# LargeDummyDevice register map
File version: 1.0
Registers are 32-bit, read-write, no defined reset value unless marked. A register's access mark holds for its fields unless they carry their own. Offsets are from the block's base; [hi:lo] are bit positions.

## PERIPHERAL_18
Base 0x40011000
0x04 REG_1 — Register 1
  [32:31] FIELD_7, [29:27] FIELD_13, [23] FIELD_1, [24:22] FIELD_10, [23:19] FIELD_9, [20:18] FIELD_6, [18:16] FIELD_4, [19:15] FIELD_5, [18:15] FIELD_12, [18:14] FIELD_2, [14:12] FIELD_11, [10:6] FIELD_8, [8:5] FIELD_3
0x08 REG_2 — Register 2
  [29] FIELD_7, [28:24] FIELD_13, [23:22] FIELD_3, [24:21] FIELD_8, [24:21] FIELD_11, [21:19] FIELD_9, [20:17] FIELD_1, [16:12] FIELD_12, [13:11] FIELD_10, [12:10] FIELD_2, [8:6] FIELD_6, [5] FIELD_4, [6:5] FIELD_5, [4:1] FIELD_14
0x0C REG_3 — Register 3
  [34:31] FIELD_13, [30:29] FIELD_20, [27] FIELD_19, [27:26] FIELD_18, [29:25] FIELD_5, [27:25] FIELD_14, [24] FIELD_12, [21] FIELD_16, [22:19] FIELD_1, [23:19] FIELD_9, [21:17] FIELD_2, [18:14] FIELD_8, [14] FIELD_17, [17:14] FIELD_24, [14:13] FIELD_22, [13:12] FIELD_21, [15:11] FIELD_11, [12:9] FIELD_3, [11:8] FIELD_6, [9:5] FIELD_4, [6:4] FIELD_10, [4] FIELD_23, [5:3] FIELD_7, [5:1] FIELD_15
0x10 REG_4 — Register 4
  [34:31] FIELD_26, [33:30] FIELD_16, [34:30] FIELD_31, [31:27] FIELD_4, [26] FIELD_5, [30:26] FIELD_29, [29:25] FIELD_6, [27:24] FIELD_11, [26:24] FIELD_24, [24] FIELD_30, [26:23] FIELD_10, [25:23] FIELD_18, [23] FIELD_28, [25:21] FIELD_8, [23:21] FIELD_21, [21:20] FIELD_17, [21:17] FIELD_22, [15:13] FIELD_14, [10:9] FIELD_12, [10:8] FIELD_7, [11:8] FIELD_20, [11:7] FIELD_3, [8:7] FIELD_13, [8:6] FIELD_19, [8:6] FIELD_27, [7:5] FIELD_9, [5:4] FIELD_1, [4:2] FIELD_2, [5:2] FIELD_15, [4:1] FIELD_25, [0] FIELD_23
0x14 REG_5 — Register 5
  [33:31] FIELD_12, [31:29] FIELD_9, [28] FIELD_11, [25] FIELD_10, [28:24] FIELD_16, [23:21] FIELD_1, [23:19] FIELD_19, [18] FIELD_20, [19:17] FIELD_8, [19:16] FIELD_3, [16] FIELD_15, [15] FIELD_2, [15] FIELD_4, [17:15] FIELD_17, [17:13] FIELD_5, [14:13] FIELD_6, [13:9] FIELD_14, [7:5] FIELD_13, [6:2] FIELD_18, [5:1] FIELD_7
0x18 REG_6 — Register 6
  [32:31] FIELD_21, [33:30] FIELD_5, [28:27] FIELD_9, [27:26] FIELD_14, [26:25] FIELD_10, [26:23] FIELD_1, [27:23] FIELD_4, [25:22] FIELD_6, [21:20] FIELD_19, [20:18] FIELD_8, [21:18] FIELD_13, [17:15] FIELD_12, [13:12] FIELD_17, [12:11] FIELD_20, [12:8] FIELD_7, [9:7] FIELD_3, [11:7] FIELD_18, [9:7] FIELD_23, [8:5] FIELD_2, [8:4] FIELD_16, [3] FIELD_15, [4:0] FIELD_11, [4:0] FIELD_22
0x1C REG_7 — Register 7
  [30:28] FIELD_19, [27:26] FIELD_24, [24:22] FIELD_13, [26:22] FIELD_17, [23:21] FIELD_18, [23:20] FIELD_15, [19:18] FIELD_5, [19:16] FIELD_1, [18:16] FIELD_14, [20:16] FIELD_25, [14] FIELD_10, [17:14] FIELD_16, [14:12] FIELD_6, [13:11] FIELD_2, [13:10] FIELD_11, [13:9] FIELD_12, [11:8] FIELD_3, [9:8] FIELD_7, [11:8] FIELD_8, [7] FIELD_23, [8:6] FIELD_4, [8:6] FIELD_21, [1] FIELD_20, [2:1] FIELD_22, [3:0] FIELD_9
0x20 REG_8 — Register 8
  [32:30] FIELD_1, [34:30] FIELD_24, [31:29] FIELD_29, [31:28] FIELD_11, [26] FIELD_6, [26] FIELD_13, [25] FIELD_28, [26:24] FIELD_30, [22] FIELD_22, [22:20] FIELD_4, [21:18] FIELD_19, [17:16] FIELD_5, [19:16] FIELD_12, [14:12] FIELD_15, [11] FIELD_2, [13:11] FIELD_7, [12:11] FIELD_23, [11:10] FIELD_9, [9] FIELD_18, [11:7] FIELD_8, [8:7] FIELD_26, [5] FIELD_20, [5:4] FIELD_16, [6:4] FIELD_21, [7:3] FIELD_3, [4:3] FIELD_14, [3:2] FIELD_17, [4:2] FIELD_25, [6:2] FIELD_27, [4:0] FIELD_10
0x24 REG_9 — Register 9
  [33:29] FIELD_5, [26:23] FIELD_6, [20] FIELD_4, [20:18] FIELD_2, [6:4] FIELD_3, [4:2] FIELD_1
0x28 REG_10 — Register 10
  [32:31] FIELD_12, [32:29] FIELD_2, [30:28] FIELD_5, [30:27] FIELD_15, [28:26] FIELD_18, [28:24] FIELD_16, [28:24] FIELD_17, [21:20] FIELD_9, [19] FIELD_10, [20:18] FIELD_3, [21:18] FIELD_6, [8:7] FIELD_1, [6] FIELD_13, [9:5] FIELD_8, [6:3] FIELD_4, [3] FIELD_7, [3:2] FIELD_11, [1:0] FIELD_14
0x2C REG_11 — Register 11
  [32:31] FIELD_4, [30] FIELD_3, [32:29] FIELD_1, [31:28] FIELD_6, [24:21] FIELD_12, [22:18] FIELD_7, [19:16] FIELD_16, [14:13] FIELD_5, [14:12] FIELD_11, [10:9] FIELD_10, [10:6] FIELD_8, [7:6] FIELD_14, [6:5] FIELD_15, [4:2] FIELD_2, [4:2] FIELD_13, [5:1] FIELD_9
0x30 REG_12 — Register 12
  [34:30] FIELD_11, [32:28] FIELD_4, [29:28] FIELD_6, [27] FIELD_7, [28:25] FIELD_9, [21:20] FIELD_1, [17] FIELD_5, [9:8] FIELD_8, [8:7] FIELD_3, [2] FIELD_2, [4:1] FIELD_10
0x34 REG_13 — Register 13
  [31:28] FIELD_7, [28] FIELD_14, [28:27] FIELD_2, [28:27] FIELD_8, [28:24] FIELD_11, [25:23] FIELD_1, [25:21] FIELD_12, [22:20] FIELD_4, [19:18] FIELD_5, [22:18] FIELD_9, [11:7] FIELD_3, [11:7] FIELD_13, [10:6] FIELD_6, [6:3] FIELD_10
0x38 REG_14 — Register 14
  [32:31] FIELD_8, [34:31] FIELD_10, [34:30] FIELD_14, [34:30] FIELD_20, [31:28] FIELD_15, [30:27] FIELD_1, [27:26] FIELD_6, [27:24] FIELD_4, [27:23] FIELD_2, [25:22] FIELD_3, [23:22] FIELD_11, [23:20] FIELD_23, [23:19] FIELD_12, [21:18] FIELD_13, [19:17] FIELD_9, [20:16] FIELD_24, [15:13] FIELD_7, [13:9] FIELD_22, [10:6] FIELD_18, [4] FIELD_25, [4:3] FIELD_5, [7:3] FIELD_19, [2] FIELD_21, [2:1] FIELD_17, [3:0] FIELD_16
0x3C REG_15 — Register 15
  [34:31] FIELD_5, [31] FIELD_6, [35:31] FIELD_19, [34:30] FIELD_4, [31:29] FIELD_27, [29:27] FIELD_21, [26] FIELD_1, [27:24] FIELD_28, [23:22] FIELD_3, [20] FIELD_8, [20] FIELD_26, [20:17] FIELD_20, [19:16] FIELD_16, [15:14] FIELD_11, [16:14] FIELD_14, [13:12] FIELD_13, [15:11] FIELD_9, [10] FIELD_15, [10] FIELD_22, [9] FIELD_18, [13:9] FIELD_24, [12:9] FIELD_25, [9:8] FIELD_10, [11:8] FIELD_17, [9:6] FIELD_2, [6:4] FIELD_12, [6:3] FIELD_23, [2:0] FIELD_7
0x40 REG_16 — Register 16
  [8:7] FIELD_1, [7:3] FIELD_2
0x44 REG_17 — Register 17
  [35:31] FIELD_5, [34:31] FIELD_15, [32:31] FIELD_17, [31:29] FIELD_9, [27] FIELD_8, [29:26] FIELD_13, [25:23] FIELD_2, [25:23] FIELD_23, [24:21] FIELD_20, [24:20] FIELD_19, [24:20] FIELD_21, [18:17] FIELD_10, [19:17] FIELD_14, [20:17] FIELD_22, [18:14] FIELD_18, [13:12] FIELD_12, [10:9] FIELD_11, [8:5] FIELD_4, [8:5] FIELD_6, [6:4] FIELD_1, [6:4] FIELD_16, [4:1] FIELD_3, [1] FIELD_7
0x48 REG_18 — Register 18
  [30] FIELD_20, [28:24] FIELD_15, [23] FIELD_2, [24:23] FIELD_12, [21] FIELD_14, [23:21] FIELD_16, [21] FIELD_22, [20:19] FIELD_5, [22:19] FIELD_8, [22:19] FIELD_19, [22:18] FIELD_13, [21:18] FIELD_17, [17:16] FIELD_3, [17:16] FIELD_7, [13:9] FIELD_9, [9:7] FIELD_4, [7:6] FIELD_10, [6:5] FIELD_6, [6:3] FIELD_11, [5:2] FIELD_18, [2:0] FIELD_1, [2:0] FIELD_21
0x4C REG_19 — Register 19
  [30] FIELD_9, [33:29] FIELD_11, [29:27] FIELD_1, [28:27] FIELD_5, [22:20] FIELD_3, [20] FIELD_10, [21:19] FIELD_2, [17:16] FIELD_4, [17:15] FIELD_15, [11:9] FIELD_8, [9] FIELD_14, [5:3] FIELD_12, [7:3] FIELD_13, [5:2] FIELD_6, [3:2] FIELD_7, [3:1] FIELD_16
0x50 REG_20 — Register 20
  [34:31] FIELD_5, [33:29] FIELD_15, [28:27] FIELD_29, [29:26] FIELD_3, [27:25] FIELD_1, [29:25] FIELD_17, [23] FIELD_8, [25:23] FIELD_14, [23:22] FIELD_28, [23:21] FIELD_16, [23:20] FIELD_6, [20] FIELD_32, [23:19] FIELD_20, [22:19] FIELD_22, [22:18] FIELD_24, [20:17] FIELD_21, [20:16] FIELD_10, [19:16] FIELD_27, [17:14] FIELD_26, [13] FIELD_11, [13] FIELD_12, [12:11] FIELD_7, [12:11] FIELD_18, [12:10] FIELD_4, [10:9] FIELD_19, [8] FIELD_23, [10:6] FIELD_2, [5] FIELD_30, [4:2] FIELD_9, [4:2] FIELD_31, [3:0] FIELD_13, [0] FIELD_25
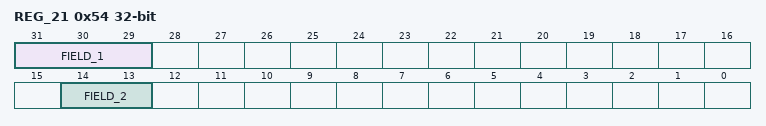
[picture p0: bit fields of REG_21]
0x54 REG_21 — Register 21
  [31:29] FIELD_1, [14:13] FIELD_2
0x58 REG_22 — Register 22
  [34:31] FIELD_8, [30] FIELD_3, [29:28] FIELD_1, [28] FIELD_6, [27:25] FIELD_7, [26:25] FIELD_9, [22] FIELD_5, [18] FIELD_2, [18:17] FIELD_4
0x5C REG_23 — Register 23
  [29:25] FIELD_3, [26:25] FIELD_11, [23] FIELD_7, [20:18] FIELD_8, [21:17] FIELD_2, [20:17] FIELD_13, [15] FIELD_14, [16:13] FIELD_18, [14:12] FIELD_6, [14:11] FIELD_5, [11:8] FIELD_9, [10:6] FIELD_12, [8:5] FIELD_1, [5:4] FIELD_10, [5:3] FIELD_15, [5:1] FIELD_4, [2:0] FIELD_16, [1:0] FIELD_17
0x60 REG_24 — Register 24
  [33:31] FIELD_4, [30:26] FIELD_3, [29:26] FIELD_8, [22:21] FIELD_11, [21:20] FIELD_10, [20:17] FIELD_9, [18:16] FIELD_7, [11] FIELD_2, [11] FIELD_6, [7:6] FIELD_5, [7:5] FIELD_1
0x64 REG_25 — Register 25
  [33:31] FIELD_5, [35:31] FIELD_20, [28:27] FIELD_10, [26] FIELD_16, [27:25] FIELD_1, [24:23] FIELD_17, [22:21] FIELD_15, [21:19] FIELD_13, [20:17] FIELD_7, [18:17] FIELD_12, [18:17] FIELD_21, [18:15] FIELD_6, [14:11] FIELD_4, [14:11] FIELD_19, [8] FIELD_18, [8:7] FIELD_14, [5] FIELD_3, [5:4] FIELD_2, [3:1] FIELD_8, [1:0] FIELD_9, [2:0] FIELD_11
0x68 REG_26 — Register 26
  [31:28] FIELD_11, [27] FIELD_14, [30:27] FIELD_16, [25] FIELD_8, [27:24] FIELD_1, [25:23] FIELD_18, [22:19] FIELD_2, [21:18] FIELD_4, [20:18] FIELD_13, [21:17] FIELD_15, [15:12] FIELD_5, [14:12] FIELD_7, [13:11] FIELD_6, [6] FIELD_10, [7:5] FIELD_17, [7:3] FIELD_12, [3:1] FIELD_3, [0] FIELD_9
0x6C REG_27 — Register 27
  [32:29] FIELD_18, [31:28] FIELD_17, [27] FIELD_27, [28:25] FIELD_25, [29:25] FIELD_28, [24] FIELD_26, [24:23] FIELD_13, [23:22] FIELD_8, [25:21] FIELD_7, [22:20] FIELD_23, [16:15] FIELD_20, [13:12] FIELD_6, [11] FIELD_1, [14:10] FIELD_19, [8] FIELD_2, [9:8] FIELD_14, [7] FIELD_12, [7:5] FIELD_5, [7:4] FIELD_22, [7:3] FIELD_3, [7:3] FIELD_21, [5:2] FIELD_11, [3:2] FIELD_15, [4:1] FIELD_4, [4:1] FIELD_9, [2:1] FIELD_16, [2:0] FIELD_10, [4:0] FIELD_24
